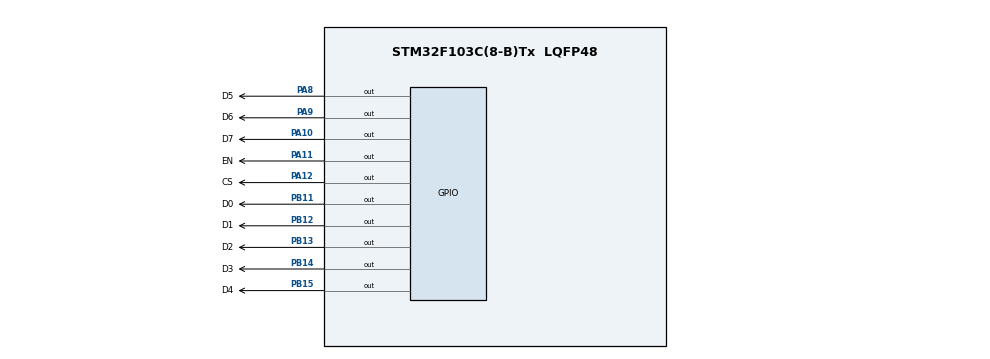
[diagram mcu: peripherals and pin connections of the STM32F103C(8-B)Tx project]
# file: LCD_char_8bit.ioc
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Mcu.Family=STM32F1
Mcu.Name=STM32F103C(8-B)Tx
Mcu.Package=LQFP48
NVIC.PriorityGroup=NVIC_PRIORITYGROUP_4
PA10.GPIO_Label=D7
PA10.Signal=GPIO_Output
PA11.GPIO_Label=EN
PA11.Signal=GPIO_Output
PA12.GPIO_Label=CS
PA12.Signal=GPIO_Output
PA13.Mode=Serial_Wire
PA13.Signal=SYS_JTMS-SWDIO
PA14.Mode=Serial_Wire
PA14.Signal=SYS_JTCK-SWCLK
PA8.GPIO_Label=D5
PA8.Signal=GPIO_Output
PA9.GPIO_Label=D6
PA9.Signal=GPIO_Output
PB11.GPIO_Label=D0
PB11.Signal=GPIO_Output
PB12.GPIO_Label=D1
PB12.Signal=GPIO_Output
PB13.GPIO_Label=D2
PB13.Signal=GPIO_Output
PB14.GPIO_Label=D3
PB14.Signal=GPIO_Output
PB15.GPIO_Label=D4
PB15.Signal=GPIO_Output
PD0-OSC_IN.Mode=HSE-External-Oscillator
PD0-OSC_IN.Signal=RCC_OSC_IN
PD1-OSC_OUT.Mode=HSE-External-Oscillator
PD1-OSC_OUT.Signal=RCC_OSC_OUT
ProjectManager.HeapSize=0x200
ProjectManager.StackSize=0x400
ProjectManager.TargetToolchain=MDK-ARM V5.27
RCC.APB1Freq_Value=8000000
RCC.APB2Freq_Value=8000000
board=custom

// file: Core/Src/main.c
/* USER CODE BEGIN Header */
/**
  ******************************************************************************
  * @file           : main.c
  * @brief          : Main program body
  ******************************************************************************
  * @attention
  *
  * <h2><center>&copy; Copyright (c) 2021 STMicroelectronics.
  * All rights reserved.</center></h2>
  *
  * This software component is licensed by ST under BSD 3-Clause license,
  * the "License"; You may not use this file except in compliance with the
  * License. You may obtain a copy of the License at:
  *                        opensource.org/licenses/BSD-3-Clause
  *
  ******************************************************************************
  */
/* USER CODE END Header */
#include "main.h"
#include "CLCD.h"
#include <stdio.h>

/* USER CODE BEGIN PV */
CLCD_Name LCD1;
uint8_t Count;
char LCD_send[16];
/* USER CODE END PV */

void SystemClock_Config(void);
static void MX_GPIO_Init(void);

int main(void)
{

  /* MCU Configuration--------------------------------------------------------*/

  /* Reset of all peripherals, Initializes the Flash interface and the Systick. */
  HAL_Init();

  /* Configure the system clock */
  SystemClock_Config();

  /* Initialize all configured peripherals */
  MX_GPIO_Init();
  /* USER CODE BEGIN 2 */
	CLCD_8BIT_Init(&LCD1, 16, 2, CS_GPIO_Port, CS_Pin, EN_GPIO_Port, EN_Pin, D0_GPIO_Port, D0_Pin, D1_GPIO_Port, D1_Pin, D2_GPIO_Port, D2_Pin, D3_GPIO_Port, D3_Pin, D4_GPIO_Port, D4_Pin, D5_GPIO_Port, D5_Pin, D6_GPIO_Port, D6_Pin, D7_GPIO_Port, D7_Pin);

  /* USER CODE END 2 */

  /* Infinite loop */
  while (1)
  {

    /* USER CODE BEGIN 3 */
		CLCD_SetCursor(&LCD1, 0, 0);
		CLCD_WriteString(&LCD1, "Hello");
		sprintf(LCD_send, "LCD dem : %d", Count);
		CLCD_SetCursor(&LCD1, 0,1);
		CLCD_WriteString(&LCD1, LCD_send);
		Count++;
		HAL_Delay(1000);

  }
  /* USER CODE END 3 */
}

void SystemClock_Config(void)
{
  RCC_OscInitTypeDef RCC_OscInitStruct = {0};
  RCC_ClkInitTypeDef RCC_ClkInitStruct = {0};

  /** Initializes the RCC Oscillators according to the specified parameters
  * in the RCC_OscInitTypeDef structure.
  */
  RCC_OscInitStruct.OscillatorType = RCC_OSCILLATORTYPE_HSI;
  RCC_OscInitStruct.HSIState = RCC_HSI_ON;
  RCC_OscInitStruct.HSICalibrationValue = RCC_HSICALIBRATION_DEFAULT;
  RCC_OscInitStruct.PLL.PLLState = RCC_PLL_NONE;
  if (HAL_RCC_OscConfig(&RCC_OscInitStruct) != HAL_OK)
  {
    Error_Handler();
  }
  /** Initializes the CPU, AHB and APB buses clocks
  */
  RCC_ClkInitStruct.ClockType = RCC_CLOCKTYPE_HCLK|RCC_CLOCKTYPE_SYSCLK
                              |RCC_CLOCKTYPE_PCLK1|RCC_CLOCKTYPE_PCLK2;
  RCC_ClkInitStruct.SYSCLKSource = RCC_SYSCLKSOURCE_HSI;
  RCC_ClkInitStruct.AHBCLKDivider = RCC_SYSCLK_DIV1;
  RCC_ClkInitStruct.APB1CLKDivider = RCC_HCLK_DIV1;
  RCC_ClkInitStruct.APB2CLKDivider = RCC_HCLK_DIV1;

  if (HAL_RCC_ClockConfig(&RCC_ClkInitStruct, FLASH_LATENCY_0) != HAL_OK)
  {
    Error_Handler();
  }
}

static void MX_GPIO_Init(void)
{
  GPIO_InitTypeDef GPIO_InitStruct = {0};

  /* GPIO Ports Clock Enable */
  __HAL_RCC_GPIOD_CLK_ENABLE();
  __HAL_RCC_GPIOB_CLK_ENABLE();
  __HAL_RCC_GPIOA_CLK_ENABLE();

  /*Configure GPIO pin Output Level */
  HAL_GPIO_WritePin(GPIOB, D0_Pin|D1_Pin|D2_Pin|D3_Pin
                          |D4_Pin, GPIO_PIN_RESET);

  /*Configure GPIO pin Output Level */
  HAL_GPIO_WritePin(GPIOA, D5_Pin|D6_Pin|D7_Pin|EN_Pin
                          |CS_Pin, GPIO_PIN_RESET);

  /*Configure GPIO pins : D0_Pin D1_Pin D2_Pin D3_Pin
                           D4_Pin */
  GPIO_InitStruct.Pin = D0_Pin|D1_Pin|D2_Pin|D3_Pin
                          |D4_Pin;
  GPIO_InitStruct.Mode = GPIO_MODE_OUTPUT_PP;
  GPIO_InitStruct.Pull = GPIO_NOPULL;
  GPIO_InitStruct.Speed = GPIO_SPEED_FREQ_LOW;
  HAL_GPIO_Init(GPIOB, &GPIO_InitStruct);

  /*Configure GPIO pins : D5_Pin D6_Pin D7_Pin EN_Pin
                           CS_Pin */
  GPIO_InitStruct.Pin = D5_Pin|D6_Pin|D7_Pin|EN_Pin
                          |CS_Pin;
  GPIO_InitStruct.Mode = GPIO_MODE_OUTPUT_PP;
  GPIO_InitStruct.Pull = GPIO_NOPULL;
  GPIO_InitStruct.Speed = GPIO_SPEED_FREQ_LOW;
  HAL_GPIO_Init(GPIOA, &GPIO_InitStruct);

}

void Error_Handler(void)
{
  __disable_irq();
  while (1)
  {
  }
}

/************************ (C) COPYRIGHT STMicroelectronics *****END OF FILE****/
